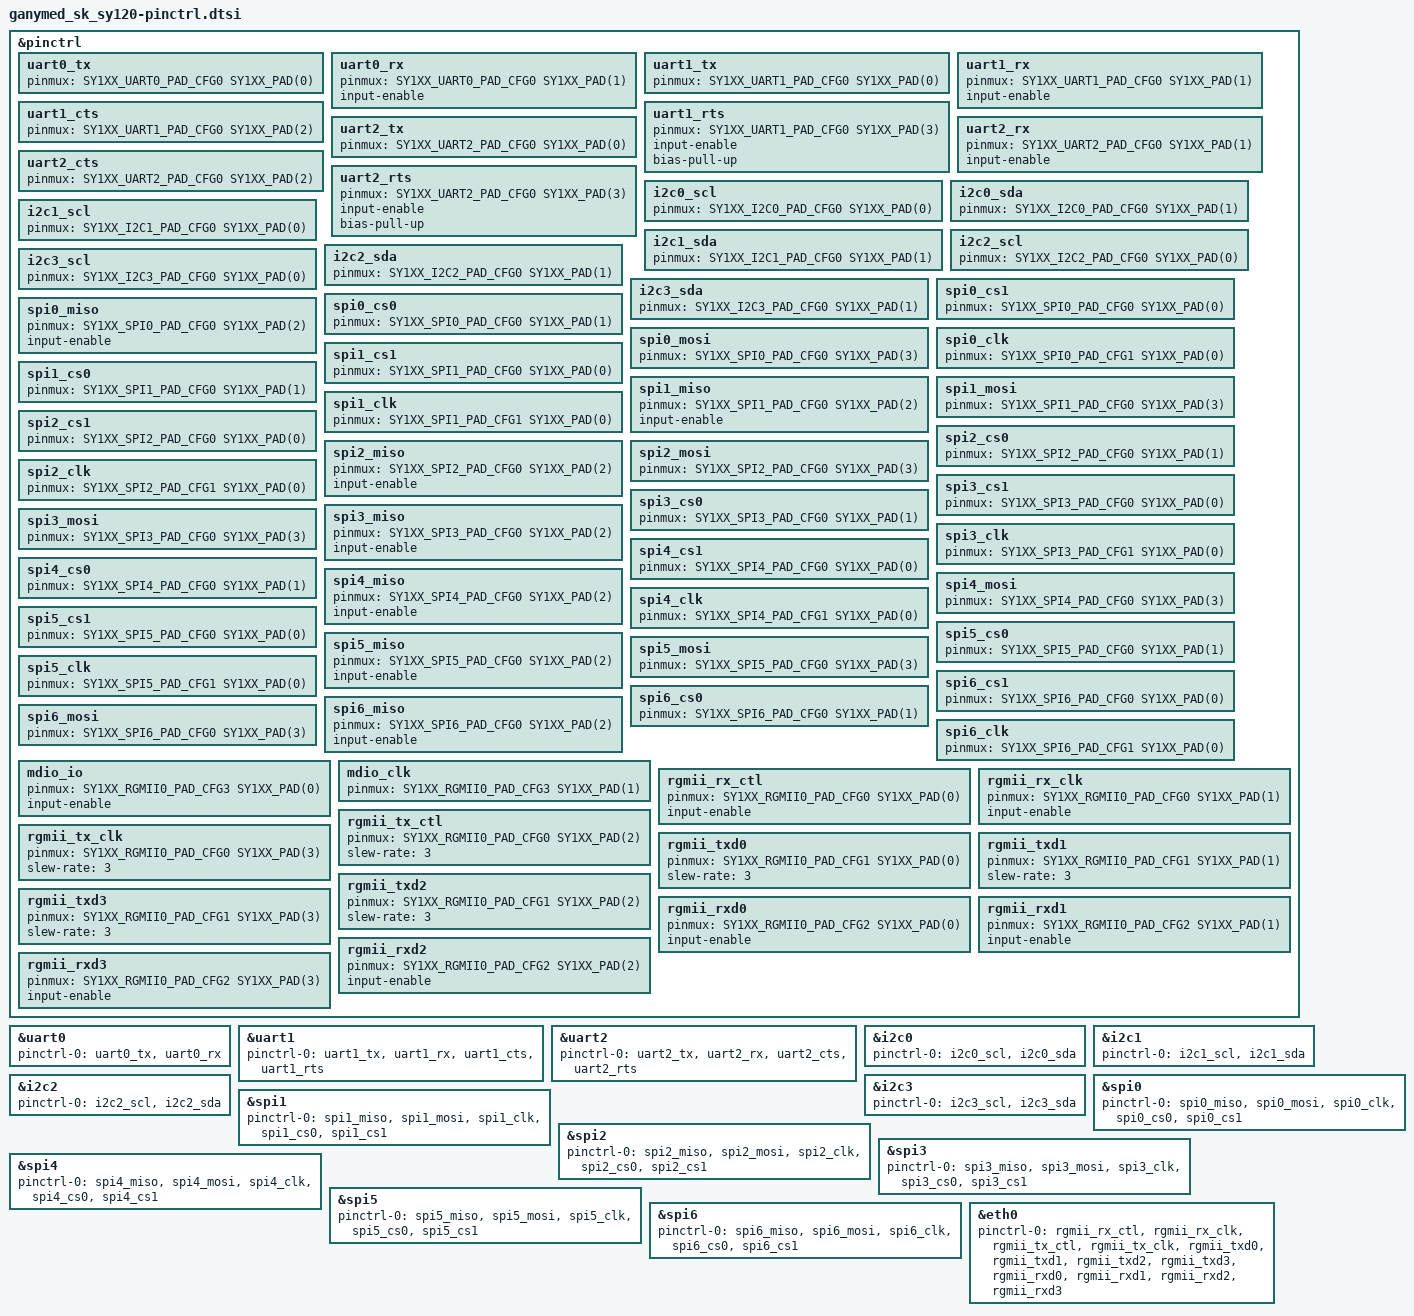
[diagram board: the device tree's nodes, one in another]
/* Copyright (c) 2025 sensry.io */
/* SPDX-License-Identifier: Apache-2.0 */

#include <zephyr/dt-bindings/pinctrl/sy1xx-pinctrl.h>

&pinctrl {
	/* UART0 */
	/omit-if-no-ref/ uart0_tx: uart0_tx {
		pinmux = <SY1XX_UART0_PAD_CFG0 SY1XX_PAD(0)>;
	};

	/omit-if-no-ref/ uart0_rx: uart0_rx {
		pinmux = <SY1XX_UART0_PAD_CFG0 SY1XX_PAD(1)>;
		input-enable;
	};

	/* UART1 */
	/omit-if-no-ref/ uart1_tx: uart1_tx {
		pinmux = <SY1XX_UART1_PAD_CFG0 SY1XX_PAD(0)>;
	};

	/omit-if-no-ref/ uart1_rx: uart1_rx {
		pinmux = <SY1XX_UART1_PAD_CFG0 SY1XX_PAD(1)>;
		input-enable;
	};

	/omit-if-no-ref/ uart1_cts: uart1_cts {
		pinmux = <SY1XX_UART1_PAD_CFG0 SY1XX_PAD(2)>;
	};

	/omit-if-no-ref/ uart1_rts: uart1_rts {
		pinmux = <SY1XX_UART1_PAD_CFG0 SY1XX_PAD(3)>;
		input-enable;
		bias-pull-up;
	};

	/* UART2 */
	/omit-if-no-ref/ uart2_tx: uart2_tx {
		pinmux = <SY1XX_UART2_PAD_CFG0 SY1XX_PAD(0)>;
	};

	/omit-if-no-ref/ uart2_rx: uart2_rx {
		pinmux = <SY1XX_UART2_PAD_CFG0 SY1XX_PAD(1)>;
		input-enable;
	};

	/omit-if-no-ref/ uart2_cts: uart2_cts {
		pinmux = <SY1XX_UART2_PAD_CFG0 SY1XX_PAD(2)>;
	};

	/omit-if-no-ref/ uart2_rts: uart2_rts {
		pinmux = <SY1XX_UART2_PAD_CFG0 SY1XX_PAD(3)>;
		input-enable;
		bias-pull-up;
	};

	/* I2C Port 0 */
	/omit-if-no-ref/ i2c0_scl: i2c0_scl {
		pinmux = <SY1XX_I2C0_PAD_CFG0 SY1XX_PAD(0)>;
	};

	/omit-if-no-ref/ i2c0_sda: i2c0_sda {
		pinmux = <SY1XX_I2C0_PAD_CFG0 SY1XX_PAD(1)>;
	};

	/* I2C Port 1 */
	/omit-if-no-ref/ i2c1_scl: i2c1_scl {
		pinmux = <SY1XX_I2C1_PAD_CFG0 SY1XX_PAD(0)>;
	};

	/omit-if-no-ref/ i2c1_sda: i2c1_sda {
		pinmux = <SY1XX_I2C1_PAD_CFG0 SY1XX_PAD(1)>;
	};

	/* I2C Port 2 */
	/omit-if-no-ref/ i2c2_scl: i2c2_scl {
		pinmux = <SY1XX_I2C2_PAD_CFG0 SY1XX_PAD(0)>;
	};

	/omit-if-no-ref/ i2c2_sda: i2c2_sda {
		pinmux = <SY1XX_I2C2_PAD_CFG0 SY1XX_PAD(1)>;
	};

	/* I2C Port 3 */
	/omit-if-no-ref/ i2c3_scl: i2c3_scl {
		pinmux = <SY1XX_I2C3_PAD_CFG0 SY1XX_PAD(0)>;
	};

	/omit-if-no-ref/ i2c3_sda: i2c3_sda {
		pinmux = <SY1XX_I2C3_PAD_CFG0 SY1XX_PAD(1)>;
	};

	/* SPI Port 0 */
	/omit-if-no-ref/ spi0_cs1: spi0_cs1 {
		pinmux = <SY1XX_SPI0_PAD_CFG0 SY1XX_PAD(0)>;
	};

	/omit-if-no-ref/ spi0_cs0: spi0_cs0 {
		pinmux = <SY1XX_SPI0_PAD_CFG0 SY1XX_PAD(1)>;
	};

	/omit-if-no-ref/ spi0_miso: spi0_miso {
		pinmux = <SY1XX_SPI0_PAD_CFG0 SY1XX_PAD(2)>;
		input-enable;
	};

	/omit-if-no-ref/ spi0_mosi: spi0_mosi {
		pinmux = <SY1XX_SPI0_PAD_CFG0 SY1XX_PAD(3)>;
	};

	/omit-if-no-ref/ spi0_clk: spi0_clk {
		pinmux = <SY1XX_SPI0_PAD_CFG1 SY1XX_PAD(0)>;
	};

	/* SPI Port 1 */
	/omit-if-no-ref/ spi1_cs1: spi1_cs1 {
		pinmux = <SY1XX_SPI1_PAD_CFG0 SY1XX_PAD(0)>;
	};

	/omit-if-no-ref/ spi1_cs0: spi1_cs0 {
		pinmux = <SY1XX_SPI1_PAD_CFG0 SY1XX_PAD(1)>;
	};

	/omit-if-no-ref/ spi1_miso: spi1_miso {
		pinmux = <SY1XX_SPI1_PAD_CFG0 SY1XX_PAD(2)>;
		input-enable;
	};

	/omit-if-no-ref/ spi1_mosi: spi1_mosi {
		pinmux = <SY1XX_SPI1_PAD_CFG0 SY1XX_PAD(3)>;
	};

	/omit-if-no-ref/ spi1_clk: spi1_clk {
		pinmux = <SY1XX_SPI1_PAD_CFG1 SY1XX_PAD(0)>;
	};

	/* SPI Port 2 */
	/omit-if-no-ref/ spi2_cs1: spi2_cs1 {
		pinmux = <SY1XX_SPI2_PAD_CFG0 SY1XX_PAD(0)>;
	};

	/omit-if-no-ref/ spi2_cs0: spi2_cs0 {
		pinmux = <SY1XX_SPI2_PAD_CFG0 SY1XX_PAD(1)>;
	};

	/omit-if-no-ref/ spi2_miso: spi2_miso {
		pinmux = <SY1XX_SPI2_PAD_CFG0 SY1XX_PAD(2)>;
		input-enable;
	};

	/omit-if-no-ref/ spi2_mosi: spi2_mosi {
		pinmux = <SY1XX_SPI2_PAD_CFG0 SY1XX_PAD(3)>;
	};

	/omit-if-no-ref/ spi2_clk: spi2_clk {
		pinmux = <SY1XX_SPI2_PAD_CFG1 SY1XX_PAD(0)>;
	};

	/* SPI Port 3 */
	/omit-if-no-ref/ spi3_cs1: spi3_cs1 {
		pinmux = <SY1XX_SPI3_PAD_CFG0 SY1XX_PAD(0)>;
	};

	/omit-if-no-ref/ spi3_cs0: spi3_cs0 {
		pinmux = <SY1XX_SPI3_PAD_CFG0 SY1XX_PAD(1)>;
	};

	/omit-if-no-ref/ spi3_miso: spi3_miso {
		pinmux = <SY1XX_SPI3_PAD_CFG0 SY1XX_PAD(2)>;
		input-enable;
	};

	/omit-if-no-ref/ spi3_mosi: spi3_mosi {
		pinmux = <SY1XX_SPI3_PAD_CFG0 SY1XX_PAD(3)>;
	};

	/omit-if-no-ref/ spi3_clk: spi3_clk {
		pinmux = <SY1XX_SPI3_PAD_CFG1 SY1XX_PAD(0)>;
	};

	/* SPI Port 4 */
	/omit-if-no-ref/ spi4_cs1: spi4_cs1 {
		pinmux = <SY1XX_SPI4_PAD_CFG0 SY1XX_PAD(0)>;
	};

	/omit-if-no-ref/ spi4_cs0: spi4_cs0 {
		pinmux = <SY1XX_SPI4_PAD_CFG0 SY1XX_PAD(1)>;
	};

	/omit-if-no-ref/ spi4_miso: spi4_miso {
		pinmux = <SY1XX_SPI4_PAD_CFG0 SY1XX_PAD(2)>;
		input-enable;
	};

	/omit-if-no-ref/ spi4_mosi: spi4_mosi {
		pinmux = <SY1XX_SPI4_PAD_CFG0 SY1XX_PAD(3)>;
	};

	/omit-if-no-ref/ spi4_clk: spi4_clk {
		pinmux = <SY1XX_SPI4_PAD_CFG1 SY1XX_PAD(0)>;
	};

	/* SPI Port 5 */
	/omit-if-no-ref/ spi5_cs1: spi5_cs1 {
		pinmux = <SY1XX_SPI5_PAD_CFG0 SY1XX_PAD(0)>;
	};

	/omit-if-no-ref/ spi5_cs0: spi5_cs0 {
		pinmux = <SY1XX_SPI5_PAD_CFG0 SY1XX_PAD(1)>;
	};

	/omit-if-no-ref/ spi5_miso: spi5_miso {
		pinmux = <SY1XX_SPI5_PAD_CFG0 SY1XX_PAD(2)>;
		input-enable;
	};

	/omit-if-no-ref/ spi5_mosi: spi5_mosi {
		pinmux = <SY1XX_SPI5_PAD_CFG0 SY1XX_PAD(3)>;
	};

	/omit-if-no-ref/ spi5_clk: spi5_clk {
		pinmux = <SY1XX_SPI5_PAD_CFG1 SY1XX_PAD(0)>;
	};

	/* SPI Port 6 */
	/omit-if-no-ref/ spi6_cs1: spi6_cs1 {
		pinmux = <SY1XX_SPI6_PAD_CFG0 SY1XX_PAD(0)>;
	};

	/omit-if-no-ref/ spi6_cs0: spi6_cs0 {
		pinmux = <SY1XX_SPI6_PAD_CFG0 SY1XX_PAD(1)>;
	};

	/omit-if-no-ref/ spi6_miso: spi6_miso {
		pinmux = <SY1XX_SPI6_PAD_CFG0 SY1XX_PAD(2)>;
		input-enable;
	};

	/omit-if-no-ref/ spi6_mosi: spi6_mosi {
		pinmux = <SY1XX_SPI6_PAD_CFG0 SY1XX_PAD(3)>;
	};

	/omit-if-no-ref/ spi6_clk: spi6_clk {
		pinmux = <SY1XX_SPI6_PAD_CFG1 SY1XX_PAD(0)>;
	};

	/* MDIO */
	/omit-if-no-ref/ mdio_io: mdio_io {
		pinmux = <SY1XX_RGMII0_PAD_CFG3 SY1XX_PAD(0)>;
		input-enable;
	};

	/omit-if-no-ref/ mdio_clk: mdio_clk {
		pinmux = <SY1XX_RGMII0_PAD_CFG3 SY1XX_PAD(1)>;
	};

	/* RGMII */
	/omit-if-no-ref/ rgmii_rx_ctl: rgmii_rx_ctl {
		pinmux = <SY1XX_RGMII0_PAD_CFG0 SY1XX_PAD(0)>;
		input-enable;
	};

	/omit-if-no-ref/ rgmii_rx_clk: rgmii_rx_clk {
		pinmux = <SY1XX_RGMII0_PAD_CFG0 SY1XX_PAD(1)>;
		input-enable;
	};

	/omit-if-no-ref/ rgmii_tx_ctl: rgmii_tx_ctl {
		pinmux = <SY1XX_RGMII0_PAD_CFG0 SY1XX_PAD(2)>;
		slew-rate = <3>;
	};

	/omit-if-no-ref/ rgmii_tx_clk: rgmii_tx_clk {
		pinmux = <SY1XX_RGMII0_PAD_CFG0 SY1XX_PAD(3)>;
		slew-rate = <3>;
	};

	/omit-if-no-ref/ rgmii_txd0: rgmii_txd0 {
		pinmux = <SY1XX_RGMII0_PAD_CFG1 SY1XX_PAD(0)>;
		slew-rate = <3>;
	};

	/omit-if-no-ref/ rgmii_txd1: rgmii_txd1 {
		pinmux = <SY1XX_RGMII0_PAD_CFG1 SY1XX_PAD(1)>;
		slew-rate = <3>;
	};

	/omit-if-no-ref/ rgmii_txd2: rgmii_txd2 {
		pinmux = <SY1XX_RGMII0_PAD_CFG1 SY1XX_PAD(2)>;
		slew-rate = <3>;
	};

	/omit-if-no-ref/ rgmii_txd3: rgmii_txd3 {
		pinmux = <SY1XX_RGMII0_PAD_CFG1 SY1XX_PAD(3)>;
		slew-rate = <3>;
	};

	/omit-if-no-ref/ rgmii_rxd0: rgmii_rxd0 {
		pinmux = <SY1XX_RGMII0_PAD_CFG2 SY1XX_PAD(0)>;
		input-enable;
	};

	/omit-if-no-ref/ rgmii_rxd1: rgmii_rxd1 {
		pinmux = <SY1XX_RGMII0_PAD_CFG2 SY1XX_PAD(1)>;
		input-enable;
	};

	/omit-if-no-ref/ rgmii_rxd2: rgmii_rxd2 {
		pinmux = <SY1XX_RGMII0_PAD_CFG2 SY1XX_PAD(2)>;
		input-enable;
	};

	/omit-if-no-ref/ rgmii_rxd3: rgmii_rxd3 {
		pinmux = <SY1XX_RGMII0_PAD_CFG2 SY1XX_PAD(3)>;
		input-enable;
	};
};

&uart0 {
	pinctrl-0 = <&uart0_tx &uart0_rx>;
	pinctrl-names = "default";
};

&uart1 {
	pinctrl-0 = <&uart1_tx &uart1_rx &uart1_cts &uart1_rts>;
	pinctrl-names = "default";
};

&uart2 {
	pinctrl-0 = <&uart2_tx &uart2_rx &uart2_cts &uart2_rts>;
	pinctrl-names = "default";
};

&i2c0 {
	pinctrl-0 = <&i2c0_scl &i2c0_sda>;
	pinctrl-names = "default";
};

&i2c1 {
	pinctrl-0 = <&i2c1_scl &i2c1_sda>;
	pinctrl-names = "default";
};

&i2c2 {
	pinctrl-0 = <&i2c2_scl &i2c2_sda>;
	pinctrl-names = "default";
};

&i2c3 {
	pinctrl-0 = <&i2c3_scl &i2c3_sda>;
	pinctrl-names = "default";
};

&spi0 {
	pinctrl-0 = <&spi0_miso &spi0_mosi &spi0_clk &spi0_cs0 &spi0_cs1>;
	pinctrl-names = "default";
};

&spi1 {
	pinctrl-0 = <&spi1_miso &spi1_mosi &spi1_clk &spi1_cs0 &spi1_cs1>;
	pinctrl-names = "default";
};

&spi2 {
	pinctrl-0 = <&spi2_miso &spi2_mosi &spi2_clk &spi2_cs0 &spi2_cs1>;
	pinctrl-names = "default";
};

&spi3 {
	pinctrl-0 = <&spi3_miso &spi3_mosi &spi3_clk &spi3_cs0 &spi3_cs1>;
	pinctrl-names = "default";
};

&spi4 {
	pinctrl-0 = <&spi4_miso &spi4_mosi &spi4_clk &spi4_cs0 &spi4_cs1>;
	pinctrl-names = "default";
};

&spi5 {
	pinctrl-0 = <&spi5_miso &spi5_mosi &spi5_clk &spi5_cs0 &spi5_cs1>;
	pinctrl-names = "default";
};

&spi6 {
	pinctrl-0 = <&spi6_miso &spi6_mosi &spi6_clk &spi6_cs0 &spi6_cs1>;
	pinctrl-names = "default";
};

&eth0 {
	pinctrl-0 = <&rgmii_rx_ctl &rgmii_rx_clk
		     &rgmii_tx_ctl &rgmii_tx_clk
		     &rgmii_txd0 &rgmii_txd1 &rgmii_txd2 &rgmii_txd3
		     &rgmii_rxd0 &rgmii_rxd1 &rgmii_rxd2 &rgmii_rxd3>;
	pinctrl-names = "default";
};
